# ADuCM320 register map
Vendor: Analog Devices Inc.; Series: ARMCM3; File version: 1.1
CPU: CM3 r2p1, little endian, no MPU, no FPU, 3 interrupt priority bits
Registers are 16-bit, read-write, no defined reset value unless marked. A register's access mark holds for its fields unless they carry their own. Offsets are from the block's base; [hi:lo] are bit positions; {n}, {i} and the like mark numbered series.

## GPIO3 — General Purpose Input Output 3
Base 0x400200C0
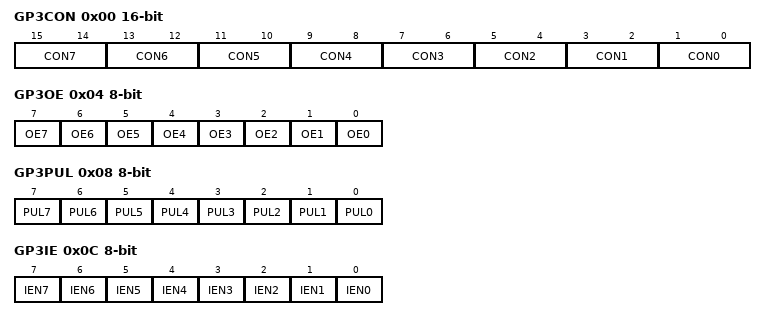
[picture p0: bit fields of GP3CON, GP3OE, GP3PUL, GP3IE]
0x00 GP3CON — GPIO Port 3 configuration
  [15:14] CON7 — p3.7 configuration bits
    0=GPIO; 1=VDAC2; 3=PLAO15
  [13:12] CON6 — p3.6 configuration bits
    0=GPIO; 1=MDIO; 3=PLAO14
  [11:10] CON5 — p3.5 configuration bits
    0=GPIO; 1=MCLK (MDIO MCK); 3=PLAO13
  [9:8] CON4 — p3.4 configuration bits
    0=GPIO; 1=PRTADDR4 (MDIO PRTADDR4); 3=PLAO12
  [7:6] CON3 — p3.3 configuration bits
    0=GPIO; 1=PRTADDR3 (MDIO PRTADDR3); 3=PLAI15
  [5:4] CON2 — p3.2 configuration bits
    0=GPIO; 1=PRTADDR2 (MDIO PRTADDR2); 3=PLAI14
  [3:2] CON1 — p3.1 configuration bits
    0=GPIO; 1=PRTADDR1 (MDIO PRTADDR1); 3=PLAI13
  [1:0] CON0 — p3.0 configuration bits
    0=GPIO; 1=PRTADDR0 (MDIO PRTADDR0); 3=PLAI12
0x04 GP3OE 8-bit — GPIO Port 3 output enable
  [all] fields
    0=DIS; 1=EN
  [n] OE{n} (n=0..7) — Pin Output Drive enable
0x08 GP3PUL 8-bit — GPIO Port 3 pullup enable
  [all] fields
    0=DIS; 1=EN
  [n] PUL{n} (n=0..7) — Pin Pull up enable
0x0C GP3IE 8-bit — GPIO Port 3 input path enable
  [all] fields
    0=DIS; 1=EN
  [n] IEN{n} (n=0..7) — Input path enable
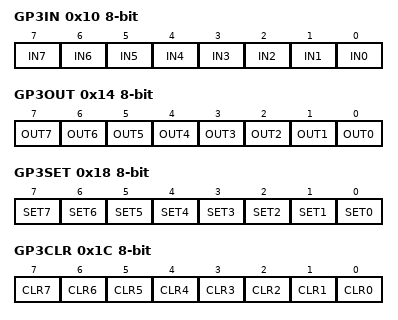
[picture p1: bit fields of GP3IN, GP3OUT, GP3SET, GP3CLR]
0x10 GP3IN 8-bit ro — GPIO Port 3 registered data input
  [all] fields
    0=LOW; 1=HIGH
  [n] IN{n} (n=0..7) — Registered data input
0x14 GP3OUT 8-bit — GPIO Port 3 data output
  [all] fields
    0=LOW; 1=HIGH
  [n] OUT{n} (n=0..7) — Data out
0x18 GP3SET 8-bit wo — GPIO Port 3 data out set
  [all] fields
    1=SET
  [n] SET{n} (n=0..7) — Set the output HIGH for the pin
0x1C GP3CLR 8-bit wo — GPIO Port 3 data out clear
  [all] fields
    1=CLR
  [n] CLR{n} (n=0..7) — Set the output low for the port pin
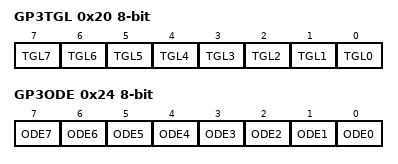
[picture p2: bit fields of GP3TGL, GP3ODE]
0x20 GP3TGL 8-bit wo — GPIO Port 3 pin toggle
  [all] fields
    1=TGL
  [n] TGL{n} (n=0..7) — Toggle the output of the port pin
0x24 GP3ODE 8-bit — GPIO Port 3 open drain enable
  [all] fields
    0=DIS; 1=EN
  [n] ODE{n} (n=0..7) — Open drain enable

## GPIO4 — General Purpose Input Output 4
Base 0x40020100
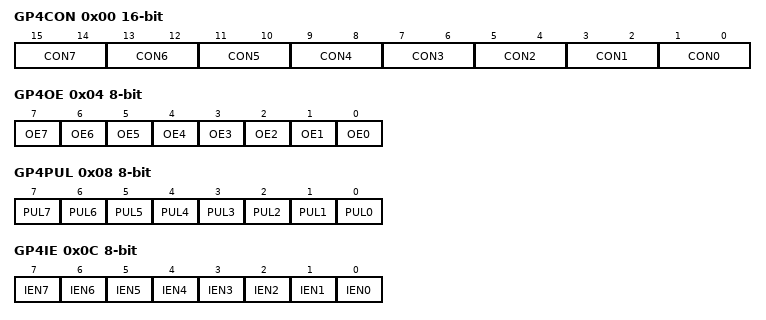
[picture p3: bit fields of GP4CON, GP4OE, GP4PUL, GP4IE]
0x00 GP4CON — GPIO Port 4 Configuration
  [15:14] CON7 range 0x00000000..0x00000003 — p4.7 configuration bits
  [13:12] CON6 range 0x00000000..0x00000003 — p4.6 configuration bits
  [11:10] CON5 range 0x00000000..0x00000003 — p4.5 configuration bits
  [9:8] CON4 range 0x00000000..0x00000003 — p4.4 configuration bits
  [7:6] CON3 range 0x00000000..0x00000003 — p4.3 configuration bits
  [5:4] CON2 range 0x00000000..0x00000003 — p4.2 configuration bits
  [3:2] CON1 range 0x00000000..0x00000003 — p4.1 configuration bits
  [1:0] CON0 — p4.0 configuration bits
    0=GPIO
0x04 GP4OE 8-bit — GPIO Port 4 output enable
  [all] fields
    0=DIS; 1=EN
  [n] OE{n} (n=0..7) — Pin Output Drive enable
0x08 GP4PUL 8-bit — GPIO Port 4 pull down enable
  [all] fields
    0=DIS; 1=EN
  [n] PUL{n} (n=0..7) — Pin Pull down enable
0x0C GP4IE 8-bit — GPIO Port 4 Input Path Enable
  [all] fields
    0=DIS; 1=EN
  [n] IEN{n} (n=0..7) — Input path enable
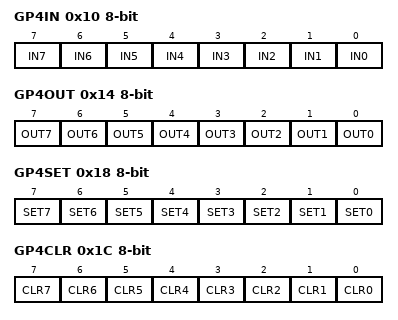
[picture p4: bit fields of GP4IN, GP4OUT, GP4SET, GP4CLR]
0x10 GP4IN 8-bit ro — GPIO Port 4 registered data input
  [all] fields
    0=LOW; 1=HIGH
  [n] IN{n} (n=0..7) — Registered data input
0x14 GP4OUT 8-bit — GPIO Port 4 data output
  [all] fields
    0=LOW; 1=HIGH
  [n] OUT{n} (n=0..7) — Data out
0x18 GP4SET 8-bit wo — GPIO Port 4 data out set
  [all] fields
    1=SET
  [n] SET{n} (n=0..7) — Set the output HIGH for the pin
0x1C GP4CLR 8-bit wo — GPIO Port 4 data out clear
  [all] fields
    1=CLR
  [n] CLR{n} (n=0..7) — Set the output low for the port pin
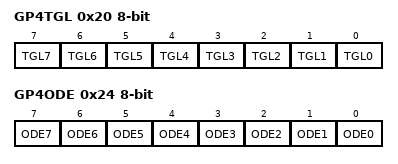
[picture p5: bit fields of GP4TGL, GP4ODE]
0x20 GP4TGL 8-bit wo — GPIO Port 4 pin toggle
  [all] fields
    1=TGL
  [n] TGL{n} (n=0..7) — Toggle the output of the port pin
0x24 GP4ODE 8-bit — GPIO Port 4 open drain enable
  [all] fields
    0=DIS; 1=EN
  [n] ODE{n} (n=0..7) — Open drain enable
